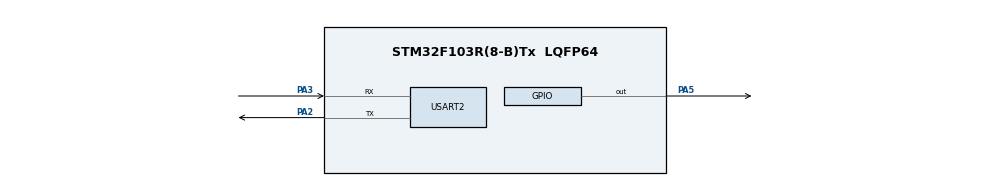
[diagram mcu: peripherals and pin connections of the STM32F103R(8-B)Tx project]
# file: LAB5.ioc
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FREERTOS.Tasks01=defaultTask,24,128,StartDefaultTask,Default,NULL,Dynamic,NULL,NULL
Mcu.Family=STM32F1
Mcu.Name=STM32F103R(8-B)Tx
Mcu.Package=LQFP64
NVIC.PriorityGroup=NVIC_PRIORITYGROUP_4
NVIC.TIM4_IRQn=true\:0\:0\:false\:false\:true\:false\:false\:true
NVIC.TimeBase=TIM4_IRQn
NVIC.TimeBaseIP=TIM4
PA13.Mode=Serial_Wire
PA13.Signal=SYS_JTMS-SWDIO
PA14.Mode=Serial_Wire
PA14.Signal=SYS_JTCK-SWCLK
PA2.Mode=Asynchronous
PA2.Signal=USART2_TX
PA3.Mode=Asynchronous
PA3.Signal=USART2_RX
PA5.Signal=GPIO_Output
ProjectManager.HeapSize=0x200
ProjectManager.StackSize=0x400
ProjectManager.TargetToolchain=STM32CubeIDE
RCC.APB1Freq_Value=8000000
RCC.APB2Freq_Value=8000000
USART2.VirtualMode=VM_ASYNC
VP_FREERTOS_VS_CMSIS_V2.Mode=CMSIS_V2
VP_SYS_VS_tim4.Mode=TIM4
board=custom

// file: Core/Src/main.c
/* USER CODE BEGIN Header */
/**
  ******************************************************************************
  * @file           : main.c
  * @brief          : Main program body
  ******************************************************************************
  * @attention
  *
  * <h2><center>&copy; Copyright (c) 2020 STMicroelectronics.
  * All rights reserved.</center></h2>
  *
  * This software component is licensed by ST under BSD 3-Clause license,
  * the "License"; You may not use this file except in compliance with the
  * License. You may obtain a copy of the License at:
  *                        opensource.org/licenses/BSD-3-Clause
  *
  ******************************************************************************
  */
/* USER CODE END Header */

#include "main.h"
#include "cmsis_os.h"

/* USER CODE BEGIN Includes */

// #include "CLI.h"

/* USER CODE END Includes */

/* USER CODE BEGIN PD */
char perChar[] = "period";
bool update = false;
/* USER CODE END PD */

UART_HandleTypeDef huart2;

/* Definitions for defaultTask */
osThreadId_t defaultTaskHandle;
const osThreadAttr_t defaultTask_attributes = {
  .name = "defaultTask",
  .priority = (osPriority_t) osPriorityNormal,
  .stack_size = 128 * 4
};

void SystemClock_Config(void);
static void MX_GPIO_Init(void);
static void MX_USART2_UART_Init(void);
void StartDefaultTask(void *argument);

int main(void)
{

  /* MCU Configuration--------------------------------------------------------*/

  /* Reset of all peripherals, Initializes the Flash interface and the Systick. */
  HAL_Init();

  /* Configure the system clock */
  SystemClock_Config();

  /* Initialize all configured peripherals */
  MX_GPIO_Init();
  MX_USART2_UART_Init();
  /* USER CODE BEGIN 2 */
  printStringBlocking(CLEAR);

    HAL_Delay(500);

    printStringBlocking(RC(1,1));

    printStringBlocking("Welcome:");// This is a program that changes the period of the LED light, type: period 500");

    printStringBlocking(CLEAR);

    printStringBlocking(RC(1,1));

    printStringBlocking("period:  500");
   // printStringBlocking(RC(1,1));

    //sprintf(str, "%i", period);

    //printStringBlocking((char*)str);

    HAL_Delay(500);

    printStringBlocking(RC(10,0));

    printStringBlocking(ROLL_TO_BOTTOM(10));

    printStringBlocking(RC(10,0));

    printStringBlocking(prompt);
  /* USER CODE END 2 */

  /* Init scheduler */
  osKernelInitialize();

  /* Create the thread(s) */
  /* creation of defaultTask */
  defaultTaskHandle = osThreadNew(StartDefaultTask, NULL, &defaultTask_attributes);

  /* Start scheduler */
  osKernelStart();

  /* We should never get here as control is now taken by the scheduler */
  /* Infinite loop */
  while (1)
  {

  }
}

void SystemClock_Config(void)
{
  RCC_OscInitTypeDef RCC_OscInitStruct = {0};
  RCC_ClkInitTypeDef RCC_ClkInitStruct = {0};

  /** Initializes the CPU, AHB and APB busses clocks
  */
  RCC_OscInitStruct.OscillatorType = RCC_OSCILLATORTYPE_HSI;
  RCC_OscInitStruct.HSIState = RCC_HSI_ON;
  RCC_OscInitStruct.HSICalibrationValue = RCC_HSICALIBRATION_DEFAULT;
  RCC_OscInitStruct.PLL.PLLState = RCC_PLL_NONE;
  if (HAL_RCC_OscConfig(&RCC_OscInitStruct) != HAL_OK)
  {
    Error_Handler();
  }
  /** Initializes the CPU, AHB and APB busses clocks
  */
  RCC_ClkInitStruct.ClockType = RCC_CLOCKTYPE_HCLK|RCC_CLOCKTYPE_SYSCLK
                              |RCC_CLOCKTYPE_PCLK1|RCC_CLOCKTYPE_PCLK2;
  RCC_ClkInitStruct.SYSCLKSource = RCC_SYSCLKSOURCE_HSI;
  RCC_ClkInitStruct.AHBCLKDivider = RCC_SYSCLK_DIV1;
  RCC_ClkInitStruct.APB1CLKDivider = RCC_HCLK_DIV1;
  RCC_ClkInitStruct.APB2CLKDivider = RCC_HCLK_DIV1;

  if (HAL_RCC_ClockConfig(&RCC_ClkInitStruct, FLASH_LATENCY_0) != HAL_OK)
  {
    Error_Handler();
  }
}

static void MX_USART2_UART_Init(void)
{

  huart2.Instance = USART2;
  huart2.Init.BaudRate = 115200;
  huart2.Init.WordLength = UART_WORDLENGTH_8B;
  huart2.Init.StopBits = UART_STOPBITS_1;
  huart2.Init.Parity = UART_PARITY_NONE;
  huart2.Init.Mode = UART_MODE_TX_RX;
  huart2.Init.HwFlowCtl = UART_HWCONTROL_NONE;
  huart2.Init.OverSampling = UART_OVERSAMPLING_16;
  if (HAL_UART_Init(&huart2) != HAL_OK)
  {
    Error_Handler();
  }

}

static void MX_GPIO_Init(void)
{
  GPIO_InitTypeDef GPIO_InitStruct = {0};

  /* GPIO Ports Clock Enable */
  __HAL_RCC_GPIOA_CLK_ENABLE();

  /*Configure GPIO pin Output Level */
  HAL_GPIO_WritePin(GPIOA, GPIO_PIN_5, GPIO_PIN_RESET);

  /*Configure GPIO pin : PA5 */
  GPIO_InitStruct.Pin = GPIO_PIN_5;
  GPIO_InitStruct.Mode = GPIO_MODE_OUTPUT_PP;
  GPIO_InitStruct.Pull = GPIO_NOPULL;
  GPIO_InitStruct.Speed = GPIO_SPEED_FREQ_LOW;
  HAL_GPIO_Init(GPIOA, &GPIO_InitStruct);

}

void StartDefaultTask(void *argument)
{
  for(;;)
  {
    osDelay(1);
  }
}

 /**
  * @brief  Period elapsed callback in non blocking mode
  * @note   This function is called  when TIM4 interrupt took place, inside
  * HAL_TIM_IRQHandler(). It makes a direct call to HAL_IncTick() to increment
  * a global variable "uwTick" used as application time base.
  * @param  htim : TIM handle
  * @retval None
  */
void HAL_TIM_PeriodElapsedCallback(TIM_HandleTypeDef *htim)
{
  if (htim->Instance == TIM4) {
    HAL_IncTick();
  }
}

void Error_Handler(void)
{
}

/************************ (C) COPYRIGHT STMicroelectronics *****END OF FILE****/
